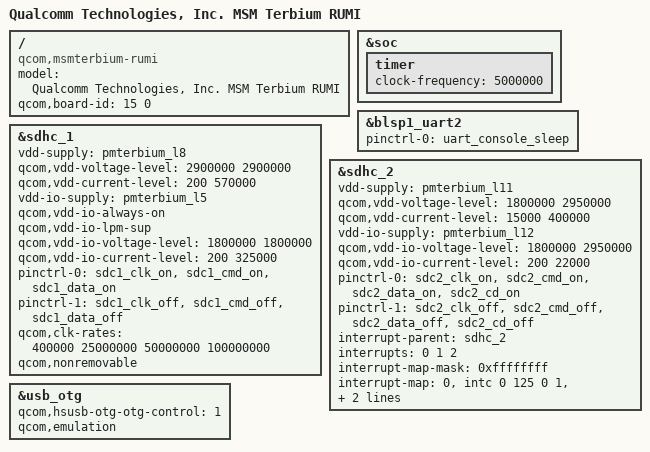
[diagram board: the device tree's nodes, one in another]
/*
 * Copyright (c) 2014-2015, The Linux Foundation. All rights reserved.
 *
 * This program is free software; you can redistribute it and/or modify
 * it under the terms of the GNU General Public License version 2 and
 * only version 2 as published by the Free Software Foundation.
 *
 * This program is distributed in the hope that it will be useful,
 * but WITHOUT ANY WARRANTY; without even the implied warranty of
 * MERCHANTABILITY or FITNESS FOR A PARTICULAR PURPOSE.  See the
 * GNU General Public License for more details.
 */

/dts-v1/;

#include "msmterbium.dtsi"

/ {
	model = "Qualcomm Technologies, Inc. MSM Terbium RUMI";
	compatible = "qcom,msmterbium-rumi", "qcom,msmterbium", "qcom,rumi";
	qcom,board-id= <15 0>;
};

&soc {
	timer {
		clock-frequency = <5000000>;
	};
};

&blsp1_uart2 {
	status = "ok";
	pinctrl-names = "default";
	pinctrl-0 = <&uart_console_sleep>;
};

&sdhc_1 {
	vdd-supply = <&pmterbium_l8>;
	qcom,vdd-voltage-level = <2900000 2900000>;
	qcom,vdd-current-level = <200 570000>;

	vdd-io-supply = <&pmterbium_l5>;
	qcom,vdd-io-always-on;
	qcom,vdd-io-lpm-sup;
	qcom,vdd-io-voltage-level = <1800000 1800000>;
	qcom,vdd-io-current-level = <200 325000>;

	pinctrl-names = "active", "sleep";
	pinctrl-0 = <&sdc1_clk_on &sdc1_cmd_on &sdc1_data_on>;
	pinctrl-1 = <&sdc1_clk_off &sdc1_cmd_off &sdc1_data_off>;

	qcom,clk-rates = <400000 25000000 50000000 100000000>;

	qcom,nonremovable;

	status = "ok";
};

&sdhc_2 {
	vdd-supply = <&pmterbium_l11>;
	qcom,vdd-voltage-level = <1800000 2950000>;
	qcom,vdd-current-level = <15000 400000>;

	vdd-io-supply = <&pmterbium_l12>;
	qcom,vdd-io-voltage-level = <1800000 2950000>;
	qcom,vdd-io-current-level = <200 22000>;

	pinctrl-names = "active", "sleep";
	pinctrl-0 = <&sdc2_clk_on &sdc2_cmd_on &sdc2_data_on &sdc2_cd_on>;
	pinctrl-1 = <&sdc2_clk_off &sdc2_cmd_off &sdc2_data_off &sdc2_cd_off>;

	#address-cells = <0>;
	interrupt-parent = <&sdhc_2>;
	interrupts = <0 1 2>;
	#interrupt-cells = <1>;
	interrupt-map-mask = <0xffffffff>;
	interrupt-map = <0 &intc 0 125 0
			1 &intc 0 221 0
			2 &msm_gpio 100 0>;
	interrupt-names = "hc_irq", "pwr_irq", "status_irq";
	cd-gpios = <&msm_gpio 100 0x1>;

	status = "ok";
};

&usb_otg {
	qcom,hsusb-otg-otg-control = <1>;
	qcom,emulation;
};
